AUTOSAR XML (schema 4-2-1)
package /ECUCompositionTypes
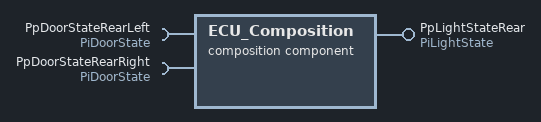
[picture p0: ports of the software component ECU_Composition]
  composition sw component type ECU_Composition
    provide port PpLightStateRear: nonqueued-sender-com-spec{data-element=DeLightState, init-value=constant-reference=CLightOff}, provided-interface=PiLightState
    require port PpDoorStateRearLeft: nonqueued-receiver-com-spec{data-element=DeDoorState, filter=data-filter-type=ALWAYS, init-value=constant-reference=CDoorClosed}, required-interface=PiDoorState
    require port PpDoorStateRearRight: nonqueued-receiver-com-spec{data-element=DeDoorState, filter=data-filter-type=ALWAYS, init-value=constant-reference=CDoorClosed}, required-interface=PiDoorState
    component CtCoApplication: type=CtCoApplication
    delegate CtCoApplication.PpDoorStateRearLeft <-> outer port PpDoorStateRearLeft
    delegate CtCoApplication.PpDoorStateRearRight <-> outer port PpDoorStateRearRight
    delegate CtCoApplication.PpLightStateRear <-> outer port PpLightStateRear
package /EndToEndProtections
  end to end protection set EndToEndConnections
package /VehicleProject
  system System: category=SYSTEM_EXTRACT
    system mapping System_MPPNG
      data-mappings:
        data-element=ECU_Composition.PpDoorStateRearRight.DeDoorState, system-signal=sig_State_RearRightDoor
        data-element=ECU_Composition.PpLightStateRear.DeLightState, system-signal=sig_RearInteriorLight
        data-element=ECU_Composition.PpDoorStateRearLeft.DeDoorState, system-signal=sig_State_RearLeftDoor
    root-software-compositions:
      root sw composition prototype ECU_Composition: software-composition=ECU_Composition
